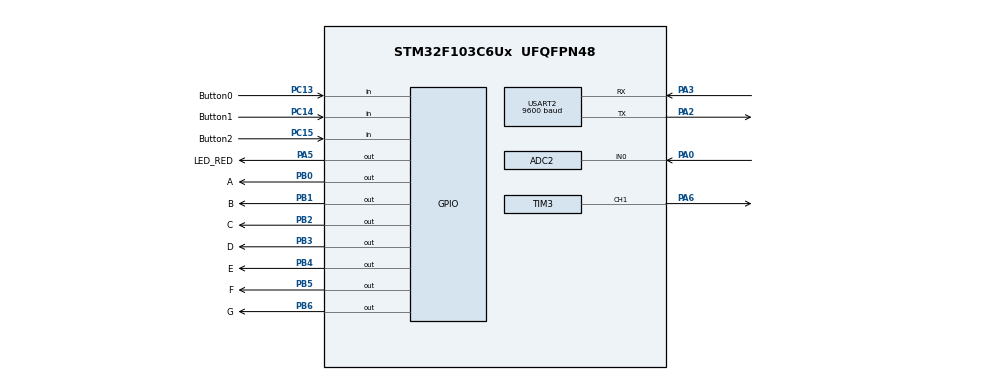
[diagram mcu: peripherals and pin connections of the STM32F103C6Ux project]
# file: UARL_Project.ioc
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ADC2.Channel-0\#ChannelRegularConversion=ADC_CHANNEL_0
ADC2.ContinuousConvMode=ENABLE
ADC2.NbrOfConversionFlag=1
ADC2.Rank-0\#ChannelRegularConversion=1
ADC2.SamplingTime-0\#ChannelRegularConversion=ADC_SAMPLETIME_1CYCLE_5
Mcu.Family=STM32F1
Mcu.Name=STM32F103C6Ux
Mcu.Package=UFQFPN48
NVIC.ADC1_2_IRQn=true\:0\:0\:false\:false\:true\:true\:true\:true
NVIC.PriorityGroup=NVIC_PRIORITYGROUP_4
NVIC.TIM2_IRQn=true\:0\:0\:false\:false\:true\:true\:true\:true
NVIC.TIM3_IRQn=true\:0\:0\:false\:false\:true\:true\:true\:true
NVIC.USART2_IRQn=true\:0\:0\:false\:false\:true\:true\:true\:true
PA0-WKUP.Signal=ADCx_IN0
PA2.Mode=Asynchronous
PA2.Signal=USART2_TX
PA3.Mode=Asynchronous
PA3.Signal=USART2_RX
PA5.GPIO_Label=LED_RED
PA5.Signal=GPIO_Output
PA6.Signal=S_TIM3_CH1
PB0.GPIO_Label=A
PB0.Signal=GPIO_Output
PB1.GPIO_Label=B
PB1.Signal=GPIO_Output
PB2.GPIO_Label=C
PB2.Signal=GPIO_Output
PB3.GPIO_Label=D
PB3.Signal=GPIO_Output
PB4.GPIO_Label=E
PB4.Signal=GPIO_Output
PB5.GPIO_Label=F
PB5.Signal=GPIO_Output
PB6.GPIO_Label=G
PB6.Signal=GPIO_Output
PC13-TAMPER-RTC.GPIO_Label=Button0
PC13-TAMPER-RTC.GPIO_PuPd=GPIO_PULLUP
PC13-TAMPER-RTC.Signal=GPIO_Input
PC14-OSC32_IN.GPIO_Label=Button1
PC14-OSC32_IN.GPIO_PuPd=GPIO_PULLUP
PC14-OSC32_IN.Signal=GPIO_Input
PC15-OSC32_OUT.GPIO_Label=Button2
PC15-OSC32_OUT.GPIO_PuPd=GPIO_PULLUP
PC15-OSC32_OUT.Signal=GPIO_Input
ProjectManager.HeapSize=0x200
ProjectManager.StackSize=0x400
ProjectManager.TargetToolchain=STM32CubeIDE
RCC.APB1Freq_Value=8000000
RCC.APB2Freq_Value=8000000
SH.ADCx_IN0.0=ADC2_IN0,IN0
SH.S_TIM3_CH1.0=TIM3_CH1,PWM Generation1 CH1
TIM2.Period=9
TIM2.Prescaler=7999
TIM3.Channel-PWM\ Generation1\ CH1=TIM_CHANNEL_1
TIM3.Period=999
TIM3.Prescaler=63
USART2.BaudRate=9600
USART2.VirtualMode=VM_ASYNC
VP_SYS_VS_ND.Mode=No_Debug
VP_TIM2_VS_ClockSourceINT.Mode=Internal
board=custom

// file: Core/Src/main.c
/* USER CODE BEGIN Header */
/**
  ******************************************************************************
  * @file           : main.c
  * @brief          : Main program body
  ******************************************************************************
  * @attention
  *
  * Copyright (c) 2022 STMicroelectronics.
  * All rights reserved.
  *
  * This software is licensed under terms that can be found in the LICENSE file
  * in the root directory of this software component.
  * If no LICENSE file comes with this software, it is provided AS-IS.
  *
  ******************************************************************************
  */
/* USER CODE END Header */
#include "main.h"

ADC_HandleTypeDef hadc2;

TIM_HandleTypeDef htim2;
TIM_HandleTypeDef htim3;

UART_HandleTypeDef huart2;

void SystemClock_Config(void);
static void MX_GPIO_Init(void);
static void MX_TIM2_Init(void);
static void MX_USART2_UART_Init(void);
static void MX_ADC2_Init(void);
static void MX_TIM3_Init(void);

/* USER CODE BEGIN 0 */
uint8_t temp = 0;

void HAL_UART_RxCpltCallback ( UART_HandleTypeDef * huart ) {
	if( huart -> Instance == USART2 ) {
	HAL_UART_Transmit (& huart2 , & temp , 1 , 50) ;
	HAL_UART_Receive_IT (& huart2 , & temp , 1) ;
	}
}
/* USER CODE END 0 */

int main(void)
{

  /* MCU Configuration--------------------------------------------------------*/

  /* Reset of all peripherals, Initializes the Flash interface and the Systick. */
  HAL_Init();

  /* Configure the system clock */
  SystemClock_Config();

  /* Initialize all configured peripherals */
  MX_GPIO_Init();
  MX_TIM2_Init();
  MX_USART2_UART_Init();
  MX_ADC2_Init();
  MX_TIM3_Init();
  /* USER CODE BEGIN 2 */
  HAL_TIM_Base_Start_IT (& htim2 );
  /* USER CODE END 2 */

  /* Infinite loop */
  /* USER CODE BEGIN WHILE */
  //char str[50];
  setTimer0(2000);
  while (1)
  {
    /* USER CODE END WHILE */

  }
}

void SystemClock_Config(void)
{
  RCC_OscInitTypeDef RCC_OscInitStruct = {0};
  RCC_ClkInitTypeDef RCC_ClkInitStruct = {0};
  RCC_PeriphCLKInitTypeDef PeriphClkInit = {0};

  /** Initializes the RCC Oscillators according to the specified parameters
  * in the RCC_OscInitTypeDef structure.
  */
  RCC_OscInitStruct.OscillatorType = RCC_OSCILLATORTYPE_HSI;
  RCC_OscInitStruct.HSIState = RCC_HSI_ON;
  RCC_OscInitStruct.HSICalibrationValue = RCC_HSICALIBRATION_DEFAULT;
  RCC_OscInitStruct.PLL.PLLState = RCC_PLL_NONE;
  if (HAL_RCC_OscConfig(&RCC_OscInitStruct) != HAL_OK)
  {
    Error_Handler();
  }

  /** Initializes the CPU, AHB and APB buses clocks
  */
  RCC_ClkInitStruct.ClockType = RCC_CLOCKTYPE_HCLK|RCC_CLOCKTYPE_SYSCLK
                              |RCC_CLOCKTYPE_PCLK1|RCC_CLOCKTYPE_PCLK2;
  RCC_ClkInitStruct.SYSCLKSource = RCC_SYSCLKSOURCE_HSI;
  RCC_ClkInitStruct.AHBCLKDivider = RCC_SYSCLK_DIV1;
  RCC_ClkInitStruct.APB1CLKDivider = RCC_HCLK_DIV1;
  RCC_ClkInitStruct.APB2CLKDivider = RCC_HCLK_DIV1;

  if (HAL_RCC_ClockConfig(&RCC_ClkInitStruct, FLASH_LATENCY_0) != HAL_OK)
  {
    Error_Handler();
  }
  PeriphClkInit.PeriphClockSelection = RCC_PERIPHCLK_ADC;
  PeriphClkInit.AdcClockSelection = RCC_ADCPCLK2_DIV2;
  if (HAL_RCCEx_PeriphCLKConfig(&PeriphClkInit) != HAL_OK)
  {
    Error_Handler();
  }
}

static void MX_ADC2_Init(void)
{

  ADC_ChannelConfTypeDef sConfig = {0};

  /** Common config
  */
  hadc2.Instance = ADC2;
  hadc2.Init.ScanConvMode = ADC_SCAN_DISABLE;
  hadc2.Init.ContinuousConvMode = ENABLE;
  hadc2.Init.DiscontinuousConvMode = DISABLE;
  hadc2.Init.ExternalTrigConv = ADC_SOFTWARE_START;
  hadc2.Init.DataAlign = ADC_DATAALIGN_RIGHT;
  hadc2.Init.NbrOfConversion = 1;
  if (HAL_ADC_Init(&hadc2) != HAL_OK)
  {
    Error_Handler();
  }

  /** Configure Regular Channel
  */
  sConfig.Channel = ADC_CHANNEL_0;
  sConfig.Rank = ADC_REGULAR_RANK_1;
  sConfig.SamplingTime = ADC_SAMPLETIME_1CYCLE_5;
  if (HAL_ADC_ConfigChannel(&hadc2, &sConfig) != HAL_OK)
  {
    Error_Handler();
  }

}

static void MX_TIM2_Init(void)
{

  TIM_ClockConfigTypeDef sClockSourceConfig = {0};
  TIM_MasterConfigTypeDef sMasterConfig = {0};

  htim2.Instance = TIM2;
  htim2.Init.Prescaler = 7999;
  htim2.Init.CounterMode = TIM_COUNTERMODE_UP;
  htim2.Init.Period = 9;
  htim2.Init.ClockDivision = TIM_CLOCKDIVISION_DIV1;
  htim2.Init.AutoReloadPreload = TIM_AUTORELOAD_PRELOAD_DISABLE;
  if (HAL_TIM_Base_Init(&htim2) != HAL_OK)
  {
    Error_Handler();
  }
  sClockSourceConfig.ClockSource = TIM_CLOCKSOURCE_INTERNAL;
  if (HAL_TIM_ConfigClockSource(&htim2, &sClockSourceConfig) != HAL_OK)
  {
    Error_Handler();
  }
  sMasterConfig.MasterOutputTrigger = TIM_TRGO_RESET;
  sMasterConfig.MasterSlaveMode = TIM_MASTERSLAVEMODE_DISABLE;
  if (HAL_TIMEx_MasterConfigSynchronization(&htim2, &sMasterConfig) != HAL_OK)
  {
    Error_Handler();
  }

}

static void MX_TIM3_Init(void)
{

  TIM_MasterConfigTypeDef sMasterConfig = {0};
  TIM_OC_InitTypeDef sConfigOC = {0};

  htim3.Instance = TIM3;
  htim3.Init.Prescaler = 63;
  htim3.Init.CounterMode = TIM_COUNTERMODE_UP;
  htim3.Init.Period = 999;
  htim3.Init.ClockDivision = TIM_CLOCKDIVISION_DIV1;
  htim3.Init.AutoReloadPreload = TIM_AUTORELOAD_PRELOAD_DISABLE;
  if (HAL_TIM_PWM_Init(&htim3) != HAL_OK)
  {
    Error_Handler();
  }
  sMasterConfig.MasterOutputTrigger = TIM_TRGO_RESET;
  sMasterConfig.MasterSlaveMode = TIM_MASTERSLAVEMODE_DISABLE;
  if (HAL_TIMEx_MasterConfigSynchronization(&htim3, &sMasterConfig) != HAL_OK)
  {
    Error_Handler();
  }
  sConfigOC.OCMode = TIM_OCMODE_PWM1;
  sConfigOC.Pulse = 0;
  sConfigOC.OCPolarity = TIM_OCPOLARITY_HIGH;
  sConfigOC.OCFastMode = TIM_OCFAST_DISABLE;
  if (HAL_TIM_PWM_ConfigChannel(&htim3, &sConfigOC, TIM_CHANNEL_1) != HAL_OK)
  {
    Error_Handler();
  }
  HAL_TIM_MspPostInit(&htim3);

}

static void MX_USART2_UART_Init(void)
{

  huart2.Instance = USART2;
  huart2.Init.BaudRate = 9600;
  huart2.Init.WordLength = UART_WORDLENGTH_8B;
  huart2.Init.StopBits = UART_STOPBITS_1;
  huart2.Init.Parity = UART_PARITY_NONE;
  huart2.Init.Mode = UART_MODE_TX_RX;
  huart2.Init.HwFlowCtl = UART_HWCONTROL_NONE;
  huart2.Init.OverSampling = UART_OVERSAMPLING_16;
  if (HAL_UART_Init(&huart2) != HAL_OK)
  {
    Error_Handler();
  }

}

static void MX_GPIO_Init(void)
{
  GPIO_InitTypeDef GPIO_InitStruct = {0};

  /* GPIO Ports Clock Enable */
  __HAL_RCC_GPIOC_CLK_ENABLE();
  __HAL_RCC_GPIOA_CLK_ENABLE();
  __HAL_RCC_GPIOB_CLK_ENABLE();

  /*Configure GPIO pin Output Level */
  HAL_GPIO_WritePin(LED_RED_GPIO_Port, LED_RED_Pin, GPIO_PIN_RESET);

  /*Configure GPIO pin Output Level */
  HAL_GPIO_WritePin(GPIOB, A_Pin|B_Pin|C_Pin|D_Pin
                          |E_Pin|F_Pin|G_Pin, GPIO_PIN_RESET);

  /*Configure GPIO pins : Button0_Pin Button1_Pin Button2_Pin */
  GPIO_InitStruct.Pin = Button0_Pin|Button1_Pin|Button2_Pin;
  GPIO_InitStruct.Mode = GPIO_MODE_INPUT;
  GPIO_InitStruct.Pull = GPIO_PULLUP;
  HAL_GPIO_Init(GPIOC, &GPIO_InitStruct);

  /*Configure GPIO pin : LED_RED_Pin */
  GPIO_InitStruct.Pin = LED_RED_Pin;
  GPIO_InitStruct.Mode = GPIO_MODE_OUTPUT_PP;
  GPIO_InitStruct.Pull = GPIO_NOPULL;
  GPIO_InitStruct.Speed = GPIO_SPEED_FREQ_LOW;
  HAL_GPIO_Init(LED_RED_GPIO_Port, &GPIO_InitStruct);

  /*Configure GPIO pins : A_Pin B_Pin C_Pin D_Pin
                           E_Pin F_Pin G_Pin */
  GPIO_InitStruct.Pin = A_Pin|B_Pin|C_Pin|D_Pin
                          |E_Pin|F_Pin|G_Pin;
  GPIO_InitStruct.Mode = GPIO_MODE_OUTPUT_PP;
  GPIO_InitStruct.Pull = GPIO_NOPULL;
  GPIO_InitStruct.Speed = GPIO_SPEED_FREQ_LOW;
  HAL_GPIO_Init(GPIOB, &GPIO_InitStruct);

}

/* USER CODE BEGIN 4 */
void HAL_TIM_PeriodElapsedCallback ( TIM_HandleTypeDef * htim ){
	timerRun();
}

/* USER CODE END 4 */

void Error_Handler(void)
{
  __disable_irq();
  while (1)
  {
  }
}
